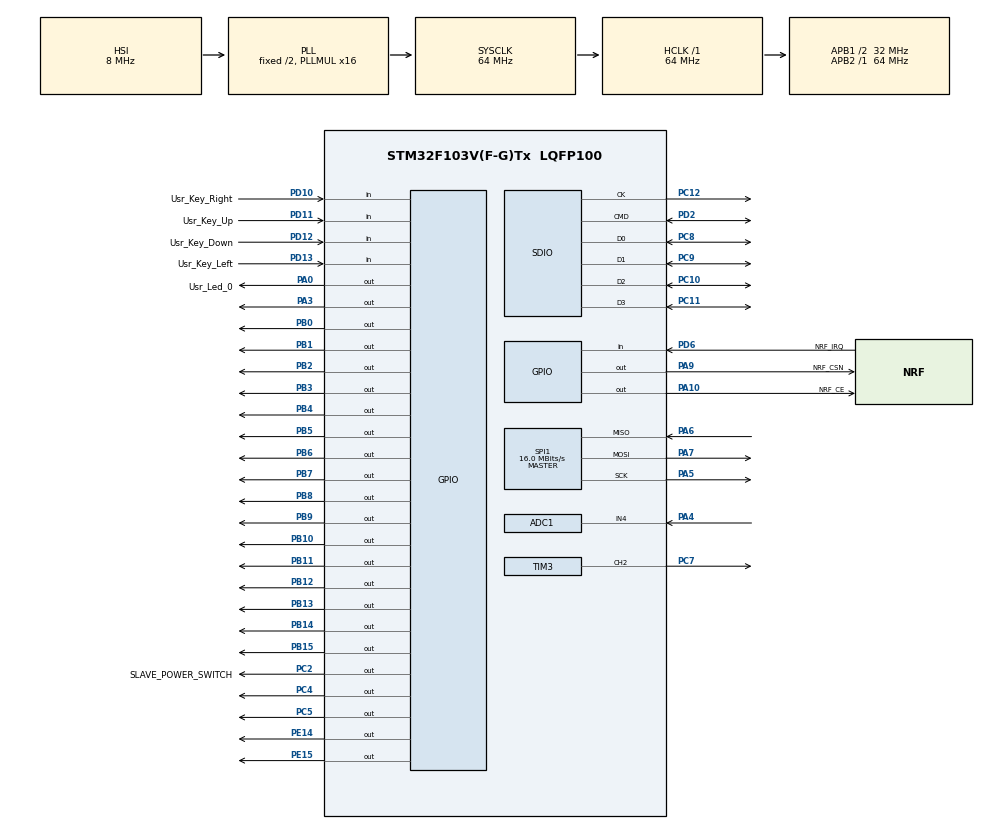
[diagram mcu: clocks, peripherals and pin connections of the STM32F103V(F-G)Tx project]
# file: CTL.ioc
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ADC1.Channel-0\#ChannelRegularConversion=ADC_CHANNEL_4
ADC1.ContinuousConvMode=ENABLE
ADC1.NbrOfConversionFlag=1
ADC1.Rank-0\#ChannelRegularConversion=1
ADC1.SamplingTime-0\#ChannelRegularConversion=ADC_SAMPLETIME_239CYCLES_5
ADC1.master=1
FATFS._CODE_PAGE=936
Mcu.Family=STM32F1
Mcu.Name=STM32F103V(F-G)Tx
Mcu.Package=LQFP100
NVIC.PriorityGroup=NVIC_PRIORITYGROUP_4
PA0-WKUP.GPIO_Label=Usr_Led_0
PA0-WKUP.Signal=GPIO_Output
PA10.GPIO_Label=NRF_CE
PA10.Signal=GPIO_Output
PA13.Mode=Serial_Wire
PA13.Signal=SYS_JTMS-SWDIO
PA14.Mode=Serial_Wire
PA14.Signal=SYS_JTCK-SWCLK
PA3.Signal=GPIO_Output
PA4.Signal=ADCx_IN4
PA5.Mode=Full_Duplex_Master
PA5.Signal=SPI1_SCK
PA6.Mode=Full_Duplex_Master
PA6.Signal=SPI1_MISO
PA7.Mode=Full_Duplex_Master
PA7.Signal=SPI1_MOSI
PA9.GPIO_Label=NRF_CSN
PA9.Signal=GPIO_Output
PB0.Signal=GPIO_Output
PB1.Signal=GPIO_Output
PB10.Signal=GPIO_Output
PB11.Signal=GPIO_Output
PB12.Signal=GPIO_Output
PB13.Signal=GPIO_Output
PB14.Signal=GPIO_Output
PB15.Signal=GPIO_Output
PB2.Signal=GPIO_Output
PB3.Signal=GPIO_Output
PB4.Signal=GPIO_Output
PB5.Signal=GPIO_Output
PB6.Signal=GPIO_Output
PB7.Signal=GPIO_Output
PB8.Signal=GPIO_Output
PB9.Signal=GPIO_Output
PC10.Mode=SD_4_bits_Wide_bus
PC10.Signal=SDIO_D2
PC11.Mode=SD_4_bits_Wide_bus
PC11.Signal=SDIO_D3
PC12.Mode=SD_4_bits_Wide_bus
PC12.Signal=SDIO_CK
PC2.GPIO_Label=SLAVE_POWER_SWITCH
PC2.Signal=GPIO_Output
PC4.Signal=GPIO_Output
PC5.Signal=GPIO_Output
PC7.Signal=S_TIM3_CH2
PC8.Mode=SD_4_bits_Wide_bus
PC8.Signal=SDIO_D0
PC9.Mode=SD_4_bits_Wide_bus
PC9.Signal=SDIO_D1
PD10.GPIO_Label=Usr_Key_Right
PD10.GPIO_PuPd=GPIO_PULLUP
PD10.Signal=GPIO_Input
PD11.GPIO_Label=Usr_Key_Up
PD11.GPIO_PuPd=GPIO_PULLUP
PD11.Signal=GPIO_Input
PD12.GPIO_Label=Usr_Key_Down
PD12.GPIO_PuPd=GPIO_PULLUP
PD12.Signal=GPIO_Input
PD13.GPIO_Label=Usr_Key_Left
PD13.GPIO_PuPd=GPIO_PULLUP
PD13.Signal=GPIO_Input
PD2.Mode=SD_4_bits_Wide_bus
PD2.Signal=SDIO_CMD
PD6.GPIO_Label=NRF_IRQ
PD6.GPIO_PuPd=GPIO_PULLUP
PD6.Signal=GPIO_Input
PE14.Signal=GPIO_Output
PE15.Signal=GPIO_Output
ProjectManager.HeapSize=0x200
ProjectManager.StackSize=0x800
ProjectManager.TargetToolchain=MDK-ARM V5
RCC.ADCPresc=RCC_ADCPCLK2_DIV8
RCC.AHBFreq_Value=64000000
RCC.APB1CLKDivider=RCC_HCLK_DIV2
RCC.APB1Freq_Value=32000000
RCC.APB1TimFreq_Value=64000000
RCC.APB2Freq_Value=64000000
RCC.APB2TimFreq_Value=64000000
RCC.HCLKFreq_Value=64000000
RCC.PLLMUL=RCC_PLL_MUL16
RCC.SYSCLKFreq_VALUE=64000000
RCC.SYSCLKSource=RCC_SYSCLKSOURCE_PLLCLK
RCC.USBFreq_Value=64000000
SDIO.ClockDiv=10
SH.ADCx_IN4.0=ADC1_IN4,IN4
SH.S_TIM3_CH2.0=TIM3_CH2,PWM Generation2 CH2
SPI1.BaudRatePrescaler=SPI_BAUDRATEPRESCALER_4
SPI1.CalculateBaudRate=16.0 MBits/s
SPI1.Direction=SPI_DIRECTION_2LINES
SPI1.Mode=SPI_MODE_MASTER
SPI1.VirtualType=VM_MASTER
TIM3.Channel-PWM\ Generation2\ CH2=TIM_CHANNEL_2
TIM3.Period=499
TIM3.Prescaler=63
TIM3.Pulse-PWM\ Generation2\ CH2=249
VP_FATFS_VS_SDIO.Mode=SDIO
VP_TIM3_VS_ClockSourceITR.Mode=TriggerSource_ITR0
VP_TIM3_VS_ControllerModeReset.Mode=Reset Mode
board=CTL

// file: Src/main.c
/**
  ******************************************************************************
  * File Name          : main.c
  * Description        : Main program body
  ******************************************************************************
  * This notice applies to any and all portions of this file
  * that are not between comment pairs USER CODE BEGIN and
  * USER CODE END. Other portions of this file, whether
  * inserted by the user or by software development tools
  * are owned by their respective copyright owners.
  *
  * Copyright (c) 2017 STMicroelectronics International N.V.
  * All rights reserved.
  *
  * Redistribution and use in source and binary forms, with or without
  * modification, are permitted, provided that the following conditions are met:
  *
  * 1. Redistribution of source code must retain the above copyright notice,
  *    this list of conditions and the following disclaimer.
  * 2. Redistributions in binary form must reproduce the above copyright notice,
  *    this list of conditions and the following disclaimer in the documentation
  *    and/or other materials provided with the distribution.
  * 3. Neither the name of STMicroelectronics nor the names of other
  *    contributors to this software may be used to endorse or promote products
  *    derived from this software without specific written permission.
  * 4. This software, including modifications and/or derivative works of this
  *    software, must execute solely and exclusively on microcontroller or
  *    microprocessor devices manufactured by or for STMicroelectronics.
  * 5. Redistribution and use of this software other than as permitted under
  *    this license is void and will automatically terminate your rights under
  *    this license.
  *
  * THIS SOFTWARE IS PROVIDED BY STMICROELECTRONICS AND CONTRIBUTORS "AS IS"
  * AND ANY EXPRESS, IMPLIED OR STATUTORY WARRANTIES, INCLUDING, BUT NOT
  * LIMITED TO, THE IMPLIED WARRANTIES OF MERCHANTABILITY, FITNESS FOR A
  * PARTICULAR PURPOSE AND NON-INFRINGEMENT OF THIRD PARTY INTELLECTUAL PROPERTY
  * RIGHTS ARE DISCLAIMED TO THE FULLEST EXTENT PERMITTED BY LAW. IN NO EVENT
  * SHALL STMICROELECTRONICS OR CONTRIBUTORS BE LIABLE FOR ANY DIRECT, INDIRECT,
  * INCIDENTAL, SPECIAL, EXEMPLARY, OR CONSEQUENTIAL DAMAGES (INCLUDING, BUT NOT
  * LIMITED TO, PROCUREMENT OF SUBSTITUTE GOODS OR SERVICES; LOSS OF USE, DATA,
  * OR PROFITS; OR BUSINESS INTERRUPTION) HOWEVER CAUSED AND ON ANY THEORY OF
  * LIABILITY, WHETHER IN CONTRACT, STRICT LIABILITY, OR TORT (INCLUDING
  * NEGLIGENCE OR OTHERWISE) ARISING IN ANY WAY OUT OF THE USE OF THIS SOFTWARE,
  * EVEN IF ADVISED OF THE POSSIBILITY OF SUCH DAMAGE.
  *
  ******************************************************************************
  */
#include "main.h"
#include "stm32f1xx_hal.h"
#include "adc.h"
#include "fatfs.h"
#include "sdio.h"
#include "spi.h"
#include "tim.h"
#include "gpio.h"

/* USER CODE BEGIN PV */
/* Private variables ---------------------------------------------------------*/

/* USER CODE END PV */

void SystemClock_Config(void);

/* USER CODE BEGIN PFP */
/* Private function prototypes -----------------------------------------------*/

/* USER CODE END PFP */

/* USER CODE BEGIN 0 */
extern uint32_t Unity_check(void);
extern void Unit_Handle(void *arg);
/* USER CODE END 0 */

int main(void)
{

  /* USER CODE BEGIN 1 */
  uint32_t flag;
  /* USER CODE END 1 */

  /* MCU Configuration----------------------------------------------------------*/

  /* Reset of all peripherals, Initializes the Flash interface and the Systick. */
  HAL_Init();

  /* Configure the system clock */
  SystemClock_Config();

  /* Initialize all configured peripherals */
  MX_GPIO_Init();
  MX_SDIO_SD_Init();
  MX_SPI1_Init();
  MX_FATFS_Init();
  MX_TIM3_Init();
  MX_ADC1_Init();

  /* USER CODE BEGIN 2 */
	HAL_Delay(500);
	flag = Unity_check();

  ADC_LL_Start();

  if (__HAL_RCC_GET_FLAG(RCC_FLAG_SFTRST) == 0)
  {
    HAL_NVIC_SystemReset();
  }

  while (flag);
  /* USER CODE END 2 */

  /* Infinite loop */
  while (1)
  {

  /* USER CODE BEGIN 3 */
		Unit_Handle(0);
  }
  /* USER CODE END 3 */

}

/** System Clock Configuration
*/
void SystemClock_Config(void)
{

  RCC_OscInitTypeDef RCC_OscInitStruct;
  RCC_ClkInitTypeDef RCC_ClkInitStruct;
  RCC_PeriphCLKInitTypeDef PeriphClkInit;

    /**Initializes the CPU, AHB and APB busses clocks
    */
  RCC_OscInitStruct.OscillatorType = RCC_OSCILLATORTYPE_HSI;
  RCC_OscInitStruct.HSIState = RCC_HSI_ON;
  RCC_OscInitStruct.HSICalibrationValue = 16;
  RCC_OscInitStruct.PLL.PLLState = RCC_PLL_ON;
  RCC_OscInitStruct.PLL.PLLSource = RCC_PLLSOURCE_HSI_DIV2;
  RCC_OscInitStruct.PLL.PLLMUL = RCC_PLL_MUL16;
  if (HAL_RCC_OscConfig(&RCC_OscInitStruct) != HAL_OK)
  {
    _Error_Handler(__FILE__, __LINE__);
  }

    /**Initializes the CPU, AHB and APB busses clocks
    */
  RCC_ClkInitStruct.ClockType = RCC_CLOCKTYPE_HCLK|RCC_CLOCKTYPE_SYSCLK
                              |RCC_CLOCKTYPE_PCLK1|RCC_CLOCKTYPE_PCLK2;
  RCC_ClkInitStruct.SYSCLKSource = RCC_SYSCLKSOURCE_PLLCLK;
  RCC_ClkInitStruct.AHBCLKDivider = RCC_SYSCLK_DIV1;
  RCC_ClkInitStruct.APB1CLKDivider = RCC_HCLK_DIV2;
  RCC_ClkInitStruct.APB2CLKDivider = RCC_HCLK_DIV1;

  if (HAL_RCC_ClockConfig(&RCC_ClkInitStruct, FLASH_LATENCY_2) != HAL_OK)
  {
    _Error_Handler(__FILE__, __LINE__);
  }

  PeriphClkInit.PeriphClockSelection = RCC_PERIPHCLK_ADC;
  PeriphClkInit.AdcClockSelection = RCC_ADCPCLK2_DIV8;
  if (HAL_RCCEx_PeriphCLKConfig(&PeriphClkInit) != HAL_OK)
  {
    _Error_Handler(__FILE__, __LINE__);
  }

    /**Configure the Systick interrupt time
    */
  HAL_SYSTICK_Config(HAL_RCC_GetHCLKFreq()/1000);

    /**Configure the Systick
    */
  HAL_SYSTICK_CLKSourceConfig(SYSTICK_CLKSOURCE_HCLK);

  /* SysTick_IRQn interrupt configuration */
  HAL_NVIC_SetPriority(SysTick_IRQn, 0, 0);
}

void _Error_Handler(char * file, int line)
{
  while(1)
  {
  }
}

/************************ (C) COPYRIGHT STMicroelectronics *****END OF FILE****/
